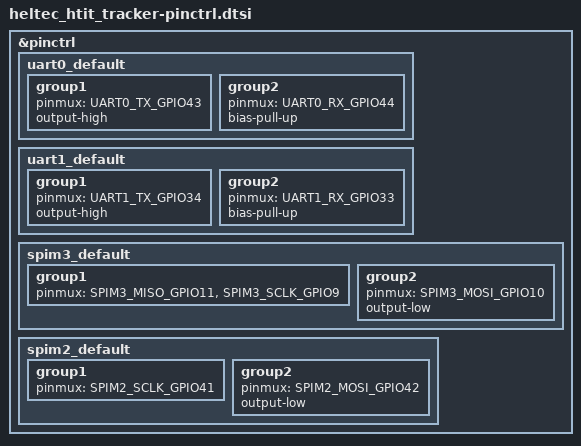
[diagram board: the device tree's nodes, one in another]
/*
 * Copyright (c) 2022 Espressif Systems (Shanghai) Co., Ltd.
 *
 * SPDX-License-Identifier: Apache-2.0
 */

#include <zephyr/dt-bindings/pinctrl/esp-pinctrl-common.h>
#include <dt-bindings/pinctrl/esp32s3-pinctrl.h>
#include <zephyr/dt-bindings/pinctrl/esp32s3-gpio-sigmap.h>

&pinctrl {

	uart0_default: uart0_default {
		group1 {
			pinmux = <UART0_TX_GPIO43>;
			output-high;
		};
		group2 {
			pinmux = <UART0_RX_GPIO44>;
			bias-pull-up;
		};
	};

	uart1_default: uart1_default {
		group1 {
			pinmux = <UART1_TX_GPIO34>;
			output-high;
		};

		group2 {
			pinmux = <UART1_RX_GPIO33>;
			bias-pull-up;
		};
	};

	spim3_default: spim3_default {
		group1 {
			pinmux = <SPIM3_MISO_GPIO11>,
				 <SPIM3_SCLK_GPIO9>;
		};
		group2 {
			pinmux = <SPIM3_MOSI_GPIO10>;
			output-low;
		};
	};

	spim2_default: spim2_default {
		group1 {
			pinmux = <SPIM2_SCLK_GPIO41>;
		};
		group2 {
			pinmux = <SPIM2_MOSI_GPIO42>;
			output-low;
		};
	};

};
